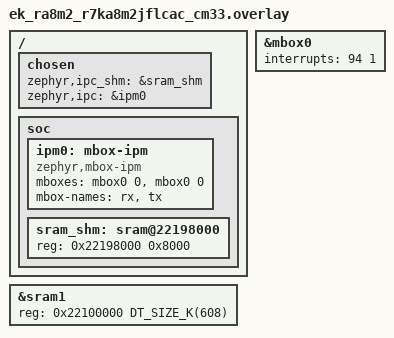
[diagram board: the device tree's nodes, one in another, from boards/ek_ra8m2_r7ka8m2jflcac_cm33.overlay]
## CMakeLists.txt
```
cmake_minimum_required(VERSION 3.28.0)
# Copyright (c) 2018 Nordic Semiconductor ASA
# Copyright (c) 2019 Linaro Limited
# Copyright 2022 NXP
#
# SPDX-License-Identifier: Apache-2.0
#


find_package(Zephyr REQUIRED HINTS $ENV{ZEPHYR_BASE})
project(openamp_remote)
message(STATUS "${BOARD} compiles as remote in this sample")

target_sources(app PRIVATE src/main.c)
target_include_directories(app PRIVATE ${CMAKE_CURRENT_SOURCE_DIR}/..)
```

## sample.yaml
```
sample:
  description: This app provides an example of how to integrate OpenAMP with Zephyr.
  name: OpenAMP example integration (remote)
tests:
  sample.ipc.openamp.remote:
    platform_allow:
      - lpcxpresso54114_m0
      - lpcxpresso55s69_cpu1
    integration_platforms:
      - lpcxpresso54114_m0
    tags: ipm
    harness: remote
```

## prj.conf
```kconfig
CONFIG_STDOUT_CONSOLE=n
CONFIG_PRINTK=n
CONFIG_IPM=y
CONFIG_HEAP_MEM_POOL_SIZE=4096
CONFIG_OPENAMP=y
CONFIG_SEGGER_RTT_BUFFER_SIZE_UP=4096
CONFIG_OPENAMP_MASTER=n
CONFIG_MAIN_STACK_SIZE=3172
```

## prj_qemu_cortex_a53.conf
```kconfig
CONFIG_STDOUT_CONSOLE=n
CONFIG_PRINTK=n
CONFIG_IPM=y
CONFIG_HEAP_MEM_POOL_SIZE=4096
CONFIG_OPENAMP=y
CONFIG_OPENAMP_MASTER=n
CONFIG_ARMV8_A_NS=y
# Disable UART driver
CONFIG_SERIAL=n

# Disable console
CONFIG_CONSOLE=n
CONFIG_UART_CONSOLE=n

# Disable serial port
CONFIG_UART_PL011=n
CONFIG_UART_PL011_PORT0=n
CONFIG_UART_INTERRUPT_DRIVEN=n
```

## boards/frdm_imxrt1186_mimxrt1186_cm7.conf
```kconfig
CONFIG_BUILD_OUTPUT_HEX=y
CONFIG_SECOND_CORE_MCUX=y
CONFIG_MBOX=y
```

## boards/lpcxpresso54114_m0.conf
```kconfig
CONFIG_SECOND_CORE_MCUX=y
CONFIG_BUILD_OUTPUT_HEX=y
```

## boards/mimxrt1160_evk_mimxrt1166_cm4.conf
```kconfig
CONFIG_BUILD_OUTPUT_INFO_HEADER=y
CONFIG_BUILD_OUTPUT_HEX=y
CONFIG_SECOND_CORE_MCUX=y
```

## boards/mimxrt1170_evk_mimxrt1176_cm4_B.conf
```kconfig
#
# Copyright 2023, NXP
#
# SPDX-License-Identifier: Apache-2.0
#
CONFIG_BUILD_OUTPUT_INFO_HEADER=y
CONFIG_BUILD_OUTPUT_HEX=y
CONFIG_SECOND_CORE_MCUX=y
```

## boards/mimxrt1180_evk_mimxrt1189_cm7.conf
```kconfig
CONFIG_BUILD_OUTPUT_HEX=y
CONFIG_SECOND_CORE_MCUX=y
CONFIG_IPM=y
CONFIG_IPM_MBOX=y
CONFIG_MBOX=y
```

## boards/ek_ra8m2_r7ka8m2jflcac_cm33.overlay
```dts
/*
 * Copyright (c) 2026 Renesas Electronics Corporation
 * SPDX-License-Identifier: Apache-2.0
 */

/ {
	chosen {
		/*
		 * shared memory reserved for the inter-processor communication
		 */

		zephyr,ipc_shm = &sram_shm;
		zephyr,ipc = &ipm0;
	};

	soc {
		ipm0: mbox-ipm {
			compatible = "zephyr,mbox-ipm";
			mboxes = <&mbox0 0>, <&mbox0 0>;
			mbox-names = "rx", "tx";
			status = "okay";
		};

		/* Define shared memory regions for IPC */
		sram_shm: sram@22198000 {
			reg = <0x22198000 0x8000>;
		};
	};
};

/* Redefine sram size for CPU1 */
&sram1 {
	reg = <0x22100000 DT_SIZE_K(608)>;
};

&mbox0 {
	interrupts = <94 1>;
	status = "okay";
};
```

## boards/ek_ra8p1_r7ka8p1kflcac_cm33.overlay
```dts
/*
 * Copyright (c) 2025 Renesas Electronics Corporation
 * SPDX-License-Identifier: Apache-2.0
 */

/ {
	chosen {
		/*
		 * shared memory reserved for the inter-processor communication
		 */

		zephyr,ipc_shm = &sram_shm;
		zephyr,ipc = &ipm0;
	};

	soc {
		ipm0: mbox-ipm {
			compatible = "zephyr,mbox-ipm";
			mboxes = <&mbox0 0>, <&mbox0 0>;
			mbox-names = "rx", "tx";
			status = "okay";
		};

		/* Define shared memory regions for IPC */
		sram_shm: sram@22198000 {
			reg = <0x22198000 0x8000>;
		};
	};
};

/* Redefine sram size for CPU1 */
&sram1 {
	reg = <0x22100000 DT_SIZE_K(608)>;
};

&mbox0 {
	interrupts = <94 1>;
	status = "okay";
};
```

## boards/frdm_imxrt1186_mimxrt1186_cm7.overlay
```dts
/*
 * Copyright 2026 NXP
 *
 * SPDX-License-Identifier: Apache-2.0
 */

#include <zephyr/dt-bindings/ipc_service/static_vrings.h>
#include <zephyr/dt-bindings/memory-attr/memory-attr-arm.h>

/ {
	chosen {
		/*
		 * shared memory reserved for the inter-processor communication
		 */

		zephyr,ipc_shm = &ocram2_sh_mem;
		zephyr,ipc = &mailbox_b;
	};

	/* Define memory regions for IPC */
	ocram2_sh_mem: memory@20500000 {
		compatible = "zephyr,memory-region", "mmio-sram";
		reg = <0x20500000 DT_SIZE_K(32)>;
		zephyr,memory-region = "OCRAM2_SH_MEM";
		zephyr,memory-attr = <DT_MEM_ARM(ATTR_MPU_IO)>;
	};

	mailbox_b: ipm-mbox {
		compatible = "zephyr,mbox-ipm";
		mboxes = <&mbox1_b 0>, <&mbox1_b 1>;
		mbox-names = "tx", "rx";
	};
};
```

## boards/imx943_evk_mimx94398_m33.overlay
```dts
/*
 * Copyright 2025 NXP
 *
 * SPDX-License-Identifier: Apache-2.0
 */

#include <zephyr/dt-bindings/ipc_service/static_vrings.h>
#include <zephyr/dt-bindings/memory-attr/memory-attr-arm.h>

/ {
	chosen {
		/*
		 * shared memory reserved for the inter-processor communication
		 */

		zephyr,ipc_shm = &dram_m33s_m71_sh_mem;
		zephyr,ipc = &mailbox_m33s_m71_for_m33s_as_remote;
	};
};
```

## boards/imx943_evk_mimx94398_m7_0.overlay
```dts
/*
 * Copyright 2025 NXP
 *
 * SPDX-License-Identifier: Apache-2.0
 */

#include <zephyr/dt-bindings/ipc_service/static_vrings.h>
#include <zephyr/dt-bindings/memory-attr/memory-attr-arm.h>

/ {
	chosen {
		/*
		 * shared memory reserved for the inter-processor communication
		 */

		zephyr,ipc_shm = &dram_m33s_m70_sh_mem;
		zephyr,ipc = &mailbox_m33s_m70_for_m70_as_remote;
	};
};
```

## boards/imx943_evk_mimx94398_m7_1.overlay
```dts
/*
 * Copyright 2025 NXP
 *
 * SPDX-License-Identifier: Apache-2.0
 */

#include <zephyr/dt-bindings/ipc_service/static_vrings.h>
#include <zephyr/dt-bindings/memory-attr/memory-attr-arm.h>

/ {
	chosen {
		/*
		 * shared memory reserved for the inter-processor communication
		 */

		zephyr,ipc_shm = &dram_m33s_m71_sh_mem;
		zephyr,ipc = &mailbox_m33s_m71_for_m71_as_remote;
	};
};
```

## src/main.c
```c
/*
 * Copyright (c) 2018, NXP
 * Copyright (c) 2018, Nordic Semiconductor ASA
 * Copyright (c) 2018-2019, Linaro Limited
 *
 * SPDX-License-Identifier: Apache-2.0
 */

#include <zephyr/kernel.h>
#include <zephyr/drivers/ipm.h>
#include <zephyr/sys/printk.h>
#include <zephyr/device.h>
#include <stdio.h>
#include <stdlib.h>
#include <string.h>

#include <openamp/open_amp.h>

#include "common.h"

#define APP_TASK_STACK_SIZE (1024)
K_THREAD_STACK_DEFINE(thread_stack, APP_TASK_STACK_SIZE);
static struct k_thread thread_data;

static const struct device *const ipm_handle =
	DEVICE_DT_GET(DT_CHOSEN(zephyr_ipc));

static metal_phys_addr_t shm_physmap[] = { SHM_START_ADDR };

static volatile unsigned int received_data;

static struct virtio_vring_info rvrings[2] = {
	[0] = {
		.info.align = VRING_ALIGNMENT,
	},
	[1] = {
		.info.align = VRING_ALIGNMENT,
	},
};
static struct virtio_device vdev;
static struct rpmsg_virtio_device rvdev;
static struct metal_io_region shm_io_data;
static struct metal_io_region *io = &shm_io_data;
static struct virtqueue *vqueue[2];

static unsigned char ipc_virtio_get_status(struct virtio_device *dev)
{
	return sys_read8(VDEV_STATUS_ADDR);
}

static uint32_t ipc_virtio_get_features(struct virtio_device *dev)
{
	return 1 << VIRTIO_RPMSG_F_NS;
}

static void ipc_virtio_notify(struct virtqueue *vq)
{
#if defined(CONFIG_SOC_AN521) || \
	defined(CONFIG_SOC_AN524) || \
	defined(CONFIG_SOC_MUSCA_B1)
	uint32_t current_core = sse_200_platform_get_cpu_id();

	ipm_send(ipm_handle, 0, current_core ? 0 : 1, 0, 1);
#else
	uint32_t dummy_data = 0x00110011; /* Some data must be provided */

	ipm_send(ipm_handle, 0, 0, &dummy_data, sizeof(dummy_data));
#endif /* #if defined(CONFIG_SOC_AN521) */
}

struct virtio_dispatch dispatch = {
	.get_status = ipc_virtio_get_status,
	.get_features = ipc_virtio_get_features,
	.notify = ipc_virtio_notify,
};

static K_SEM_DEFINE(data_sem, 0, 1);
static K_SEM_DEFINE(data_rx_sem, 0, 1);

static void platform_ipm_callback(const struct device *dev, void *context,
				  uint32_t id, volatile void *data)
{
	k_sem_give(&data_sem);
}

int endpoint_cb(struct rpmsg_endpoint *ept, void *data,
		size_t len, uint32_t src, void *priv)
{
	received_data = *((unsigned int *) data);

	k_sem_give(&data_rx_sem);

	return RPMSG_SUCCESS;
}

static K_SEM_DEFINE(ept_sem, 0, 1);

struct rpmsg_endpoint my_ept;
struct rpmsg_endpoint *ep = &my_ept;

static void rpmsg_service_unbind(struct rpmsg_endpoint *ept)
{
	(void)ept;
	rpmsg_destroy_ept(ep);
}

static unsigned int receive_message(void)
{
	while (k_sem_take(&data_rx_sem, K_NO_WAIT) != 0) {
		int status = k_sem_take(&data_sem, K_FOREVER);

		if (status == 0) {
			virtqueue_notification(vqueue[1]);
		}
	}
	return received_data;
}

static int send_message(unsigned int message)
{
	return rpmsg_send(ep, &message, sizeof(message));
}

void app_task(void *arg1, void *arg2, void *arg3)
{
	ARG_UNUSED(arg1);
	ARG_UNUSED(arg2);
	ARG_UNUSED(arg3);

	int status = 0;
	unsigned int message = 0U;
	struct rpmsg_device *rdev;
	struct metal_init_params metal_params = METAL_INIT_DEFAULTS;

	printk("\r\nOpenAMP[remote] demo started\r\n");

	status = metal_init(&metal_params);
	if (status != 0) {
		printk("metal_init: failed - error code %d\n", status);
		return;
	}

	/* declare shared memory region */
	metal_io_init(io, (void *)SHM_START_ADDR, shm_physmap, SHM_SIZE, -1, 0, NULL);

	/* setup IPM */
	if (!device_is_ready(ipm_handle)) {
		printk("IPM device is not ready\n");
		return;
	}

	ipm_register_callback(ipm_handle, platform_ipm_callback, NULL);

	status = ipm_set_enabled(ipm_handle, 1);
	if (status != 0) {
		printk("ipm_set_enabled failed\n");
		return;
	}

	/* setup vdev */
	vqueue[0] = virtqueue_allocate(VRING_SIZE);
	if (vqueue[0] == NULL) {
		printk("virtqueue_allocate failed to alloc vqueue[0]\n");
		return;
	}
	vqueue[1] = virtqueue_allocate(VRING_SIZE);
	if (vqueue[1] == NULL) {
		printk("virtqueue_allocate failed to alloc vqueue[1]\n");
		return;
	}

	vdev.role = RPMSG_REMOTE;
	vdev.vrings_num = VRING_COUNT;
	vdev.func = &dispatch;
	rvrings[0].io = io;
	rvrings[0].info.vaddr = (void *)VRING_TX_ADDRESS;
	rvrings[0].info.num_descs = VRING_SIZE;
	rvrings[0].info.align = VRING_ALIGNMENT;
	rvrings[0].vq = vqueue[0];

	rvrings[1].io = io;
	rvrings[1].info.vaddr = (void *)VRING_RX_ADDRESS;
	rvrings[1].info.num_descs = VRING_SIZE;
	rvrings[1].info.align = VRING_ALIGNMENT;
	rvrings[1].vq = vqueue[1];

	vdev.vrings_info = &rvrings[0];

	/* setup rvdev */
	status = rpmsg_init_vdev(&rvdev, &vdev, NULL, io, NULL);
	if (status != 0) {
		printk("rpmsg_init_vdev failed %d\n", status);
		return;
	}

	rdev = rpmsg_virtio_get_rpmsg_device(&rvdev);

	status = rpmsg_create_ept(ep, rdev, "k", RPMSG_ADDR_ANY,
			RPMSG_ADDR_ANY, endpoint_cb, rpmsg_service_unbind);
	if (status != 0) {
		printk("rpmsg_create_ept failed %d\n", status);
		return;
	}

	while (message < 99) {
		message = receive_message();
		printk("Remote core received a message: %d\n", message);

		message++;
		status = send_message(message);
		if (status < 0) {
			printk("send_message(%d) failed with status %d\n",
			       message, status);
			goto _cleanup;
		}
	}

_cleanup:
	rpmsg_deinit_vdev(&rvdev);
	metal_finish();

	printk("OpenAMP demo ended.\n");
}

int main(void)
{
	printk("Starting application thread!\n");
	k_thread_create(&thread_data, thread_stack, APP_TASK_STACK_SIZE,
			app_task,
			NULL, NULL, NULL, K_PRIO_COOP(7), 0, K_NO_WAIT);
	return 0;
}
```

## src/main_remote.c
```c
/*
 * Copyright (c) 2018, NXP
 * Copyright (c) 2018 Nordic Semiconductor ASA
 *
 * SPDX-License-Identifier: Apache-2.0
 *
 * This implements the remote side of an OpenAMP system.
 */

#include <zephyr.h>
#include <misc/printk.h>
#include <device.h>
#include <stdio.h>
#include <stdlib.h>
#include <string.h>

#include <openamp/open_amp.h>

#include "platform.h"
#include "resource_table.h"

#define APP_TASK_STACK_SIZE (512)
K_THREAD_STACK_DEFINE(thread_stack, APP_TASK_STACK_SIZE);
static struct k_thread thread_data;

static K_SEM_DEFINE(channel_created, 0, 1);

static K_SEM_DEFINE(message_received, 0, 1);
static volatile unsigned int received_data;

static struct rsc_table_info rsc_info;
static struct hil_proc *proc;

static struct rpmsg_channel *rp_channel;
static struct rpmsg_endpoint *rp_endpoint;

static void rpmsg_recv_callback(struct rpmsg_channel *channel, void *data,
				int data_length, void *private,
				unsigned long src)
{
	received_data = *((unsigned int *) data);
	k_sem_give(&message_received);
}

static void rpmsg_channel_created(struct rpmsg_channel *channel)
{
	rp_channel = channel;
	rp_endpoint = rpmsg_create_ept(rp_channel, rpmsg_recv_callback,
				       RPMSG_NULL, RPMSG_ADDR_ANY);
	k_sem_give(&channel_created);
}

static void rpmsg_channel_deleted(struct rpmsg_channel *channel)
{
	rpmsg_destroy_ept(rp_endpoint);
}

static unsigned int receive_message(void)
{
	while (k_sem_take(&message_received, K_NO_WAIT) != 0)
		hil_poll(proc, 0);
	return received_data;
}

static int send_message(unsigned int message)
{
	return rpmsg_send(rp_channel, &message, sizeof(message));
}

void app_task(void *arg1, void *arg2, void *arg3)
{
	ARG_UNUSED(arg1);
	ARG_UNUSED(arg2);
	ARG_UNUSED(arg3);

	struct metal_init_params metal_params = METAL_INIT_DEFAULTS;

	metal_init(&metal_params);

	proc = platform_init(RPMSG_REMOTE);
	if (proc == NULL) {
		goto _cleanup;
	}

	resource_table_init((void **) &rsc_info.rsc_tab, &rsc_info.size);

	struct remote_proc *rproc_ptr = NULL;
	int status = remoteproc_resource_init(&rsc_info, proc,
					      rpmsg_channel_created,
					      rpmsg_channel_deleted,
					      rpmsg_recv_callback,
					      &rproc_ptr, RPMSG_REMOTE);
	if (status != 0) {
		goto _cleanup;
	}

	while (k_sem_take(&channel_created, K_NO_WAIT) != 0)
		hil_poll(proc, 0);

	unsigned int message = 0U;

	while (message <= 100) {
		message = receive_message();
		message++;
		status = send_message(message);
		if (status <= 0) {
			goto _cleanup;
		}
	}

_cleanup:
	if (rproc_ptr) {
		remoteproc_resource_deinit(rproc_ptr);
	}
}

void main(void)
{
	k_thread_create(&thread_data, thread_stack, APP_TASK_STACK_SIZE,
			(k_thread_entry_t)app_task,
			NULL, NULL, NULL, K_PRIO_COOP(7), 0, 0);
}
```
